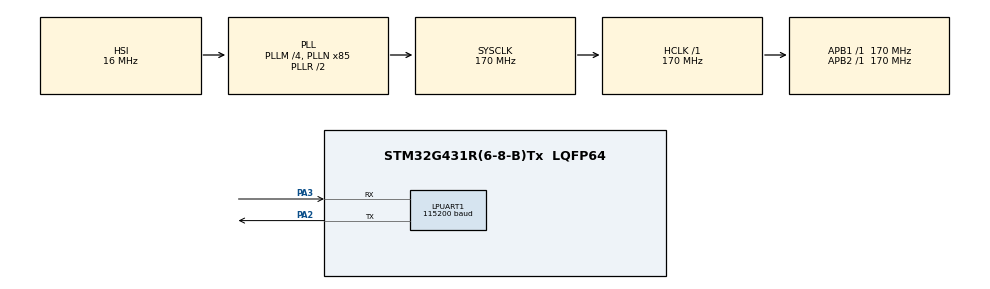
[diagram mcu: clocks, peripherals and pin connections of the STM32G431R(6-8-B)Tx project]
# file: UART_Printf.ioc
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FREERTOS.BinarySemaphores01=myBinarySem01,Dynamic,NULL
FREERTOS.Tasks01=defaultTask,0,128,StartDefaultTask,Default,NULL,Dynamic,NULL,NULL;printfTask,-3,128,StartPrintfTask,Default,NULL,Dynamic,NULL,NULL
FREERTOS.configUSE_NEWLIB_REENTRANT=1
LPUART1.BaudRate=115200
LPUART1.DMADisableonRxErrorParam-Asynchronous=UART_ADVFEATURE_DMA_ENABLEONRXERROR
LPUART1.DataInvertParam-Asynchronous=UART_ADVFEATURE_DATAINV_DISABLE
LPUART1.MSBFirstParam-Asynchronous=UART_ADVFEATURE_MSBFIRST_DISABLE
LPUART1.Mode-Asynchronous=UART_MODE_TX_RX
LPUART1.OneBitSampling=UART_ONE_BIT_SAMPLE_DISABLE
LPUART1.OverrunDisableParam-Asynchronous=UART_ADVFEATURE_OVERRUN_ENABLE
LPUART1.Parity-Asynchronous=UART_PARITY_ODD
LPUART1.RxPinLevelInvertParam-Asynchronous=UART_ADVFEATURE_RXINV_DISABLE
LPUART1.StopBits-Asynchronous=UART_STOPBITS_1
LPUART1.SwapParam-Asynchronous=UART_ADVFEATURE_SWAP_DISABLE
LPUART1.TxPinLevelInvertParam-Asynchronous=UART_ADVFEATURE_TXINV_DISABLE
LPUART1.WordLength=UART_WORDLENGTH_8B
Mcu.Family=STM32G4
Mcu.Name=STM32G431R(6-8-B)Tx
Mcu.Package=LQFP64
NVIC.PriorityGroup=NVIC_PRIORITYGROUP_4
NVIC.TIM6_DAC_IRQn=true\:15\:0\:false\:false\:true\:false\:false\:true\:true
NVIC.TimeBase=TIM6_DAC_IRQn
NVIC.TimeBaseIP=TIM6
PA2.GPIO_PuPd=GPIO_PULLUP
PA2.Mode=Asynchronous
PA2.Signal=LPUART1_TX
PA3.GPIO_PuPd=GPIO_PULLUP
PA3.Mode=Asynchronous
PA3.Signal=LPUART1_RX
ProjectManager.HeapSize=0x200
ProjectManager.StackSize=0x400
ProjectManager.TargetToolchain=STM32CubeIDE
RCC.ADC12Freq_Value=170000000
RCC.AHBFreq_Value=170000000
RCC.APB1Freq_Value=170000000
RCC.APB1TimFreq_Value=170000000
RCC.APB2Freq_Value=170000000
RCC.APB2TimFreq_Value=170000000
RCC.CortexFreq_Value=170000000
RCC.EXTERNAL_CLOCK_VALUE=12288000
RCC.HCLKFreq_Value=170000000
RCC.HSE_VALUE=24000000
RCC.HSI48_VALUE=48000000
RCC.HSI_VALUE=16000000
RCC.LSE_VALUE=32768
RCC.PLLM=RCC_PLLM_DIV4
RCC.PLLN=85
RCC.SYSCLKFreq_VALUE=170000000
RCC.SYSCLKSource=RCC_SYSCLKSOURCE_PLLCLK
RCC.USBFreq_Value=170000000
RCC.VCOOutputFreq_Value=340000000
VP_FREERTOS_VS_CMSIS_V1.Mode=CMSIS_V1
VP_SYS_VS_DBSignals.Mode=DisableDeadBatterySignals
VP_SYS_VS_tim6.Mode=TIM6
board=custom

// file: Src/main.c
/* USER CODE BEGIN Header */
/**
  ******************************************************************************
  * @file    UART/UART_Printf/Src/main.c
  * @author  MCD Application Team
  * @brief   This example shows how to retarget the C library printf function
  *          to the UART.
  ******************************************************************************
  * @attention
  *
  * Copyright (c) 2019 STMicroelectronics.
  * All rights reserved.
  *
  * This software is licensed under terms that can be found in the LICENSE file
  * in the root directory of this software component.
  * If no LICENSE file comes with this software, it is provided AS-IS.
  *
  ******************************************************************************
  */
/* USER CODE END Header */
#include "main.h"
#include "cmsis_os.h"
#include <stdarg.h>

UART_HandleTypeDef hlpuart1;

osThreadId defaultTaskHandle;
osThreadId printfTaskHandle;
osSemaphoreId myBinarySem01Handle;

void SystemClock_Config(void);
static void MX_GPIO_Init(void);
static void MX_LPUART1_UART_Init(void);
void StartDefaultTask(void const * argument);
void StartPrintfTask(void const * argument);

/* USER CODE BEGIN PFP */
#ifdef __GNUC__
/* With GCC, small printf (option LD Linker->Libraries->Small printf
   set to 'Yes') calls __io_putchar() */
#define PUTCHAR_PROTOTYPE int __io_putchar(int ch)
#else
#define PUTCHAR_PROTOTYPE int fputc(int ch, FILE *f)
#endif /* __GNUC__ */
/* USER CODE END PFP */

int main(void)
{
  /* USER CODE BEGIN 1 */

  /* STM32G4xx HAL library initialization:
       - Configure the Flash prefetch
       - Systick timer is configured by default as source of time base, but user
         can eventually implement his proper time base source (a general purpose
         timer for example or other time source), keeping in mind that Time base
         duration should be kept 1ms since PPP_TIMEOUT_VALUEs are defined and
         handled in milliseconds basis.
       - Set NVIC Group Priority to 4
       - Low Level Initialization
     */
  /* USER CODE END 1 */

  /* MCU Configuration--------------------------------------------------------*/

  /* Reset of all peripherals, Initializes the Flash interface and the Systick. */
  HAL_Init();

  /* Configure the system clock */
  SystemClock_Config();

  /* USER CODE BEGIN SysInit */
  /* Initialize BSP Led for LED2 */
  BSP_LED_Init(LED2);
  /* USER CODE END SysInit */

  /* Initialize all configured peripherals */
  MX_GPIO_Init();
  MX_LPUART1_UART_Init();
  /* USER CODE BEGIN 2 */

  /* Output a message on Hyperterminal using printf function */
  printf("\n\r UART Printf Example: retarget the C library printf function to the UART\n\r");

  /* USER CODE END 2 */

  /* Create the semaphores(s) */
  /* definition and creation of myBinarySem01 */
  osSemaphoreDef(myBinarySem01);
  myBinarySem01Handle = osSemaphoreCreate(osSemaphore(myBinarySem01), 1);

  /* Create the thread(s) */
  /* definition and creation of defaultTask */
  osThreadDef(defaultTask, StartDefaultTask, osPriorityNormal, 0, 128);
  defaultTaskHandle = osThreadCreate(osThread(defaultTask), NULL);

  /* definition and creation of printfTask */
  osThreadDef(printfTask, StartPrintfTask, osPriorityIdle, 0, 128);
  printfTaskHandle = osThreadCreate(osThread(printfTask), NULL);

  /* Start scheduler */
  osKernelStart();

  /* We should never get here as control is now taken by the scheduler */
  /* Infinite loop */
  while (1)
  {

  }
}

void SystemClock_Config(void)
{
  RCC_OscInitTypeDef RCC_OscInitStruct = {0};
  RCC_ClkInitTypeDef RCC_ClkInitStruct = {0};

  /** Configure the main internal regulator output voltage
  */
  HAL_PWREx_ControlVoltageScaling(PWR_REGULATOR_VOLTAGE_SCALE1_BOOST);

  /** Initializes the RCC Oscillators according to the specified parameters
  * in the RCC_OscInitTypeDef structure.
  */
  RCC_OscInitStruct.OscillatorType = RCC_OSCILLATORTYPE_HSI;
  RCC_OscInitStruct.HSIState = RCC_HSI_ON;
  RCC_OscInitStruct.HSICalibrationValue = RCC_HSICALIBRATION_DEFAULT;
  RCC_OscInitStruct.PLL.PLLState = RCC_PLL_ON;
  RCC_OscInitStruct.PLL.PLLSource = RCC_PLLSOURCE_HSI;
  RCC_OscInitStruct.PLL.PLLM = RCC_PLLM_DIV4;
  RCC_OscInitStruct.PLL.PLLN = 85;
  RCC_OscInitStruct.PLL.PLLP = RCC_PLLP_DIV2;
  RCC_OscInitStruct.PLL.PLLQ = RCC_PLLQ_DIV2;
  RCC_OscInitStruct.PLL.PLLR = RCC_PLLR_DIV2;
  if (HAL_RCC_OscConfig(&RCC_OscInitStruct) != HAL_OK)
  {
    Error_Handler();
  }

  /** Initializes the CPU, AHB and APB buses clocks
  */
  RCC_ClkInitStruct.ClockType = RCC_CLOCKTYPE_HCLK|RCC_CLOCKTYPE_SYSCLK
                              |RCC_CLOCKTYPE_PCLK1|RCC_CLOCKTYPE_PCLK2;
  RCC_ClkInitStruct.SYSCLKSource = RCC_SYSCLKSOURCE_PLLCLK;
  RCC_ClkInitStruct.AHBCLKDivider = RCC_SYSCLK_DIV1;
  RCC_ClkInitStruct.APB1CLKDivider = RCC_HCLK_DIV1;
  RCC_ClkInitStruct.APB2CLKDivider = RCC_HCLK_DIV1;

  if (HAL_RCC_ClockConfig(&RCC_ClkInitStruct, FLASH_LATENCY_4) != HAL_OK)
  {
    Error_Handler();
  }
}

static void MX_LPUART1_UART_Init(void)
{

  hlpuart1.Instance = LPUART1;
  hlpuart1.Init.BaudRate = 115200;
  hlpuart1.Init.WordLength = UART_WORDLENGTH_8B;
  hlpuart1.Init.StopBits = UART_STOPBITS_1;
  hlpuart1.Init.Parity = UART_PARITY_NONE;
  hlpuart1.Init.Mode = UART_MODE_TX_RX;
  hlpuart1.Init.HwFlowCtl = UART_HWCONTROL_NONE;
  hlpuart1.Init.OneBitSampling = UART_ONE_BIT_SAMPLE_DISABLE;
  hlpuart1.Init.ClockPrescaler = UART_PRESCALER_DIV1;
  hlpuart1.AdvancedInit.AdvFeatureInit = UART_ADVFEATURE_NO_INIT;
  if (HAL_UART_Init(&hlpuart1) != HAL_OK)
  {
    Error_Handler();
  }
  if (HAL_UARTEx_SetTxFifoThreshold(&hlpuart1, UART_TXFIFO_THRESHOLD_1_8) != HAL_OK)
  {
    Error_Handler();
  }
  if (HAL_UARTEx_SetRxFifoThreshold(&hlpuart1, UART_RXFIFO_THRESHOLD_1_8) != HAL_OK)
  {
    Error_Handler();
  }
  if (HAL_UARTEx_DisableFifoMode(&hlpuart1) != HAL_OK)
  {
    Error_Handler();
  }

}

static void MX_GPIO_Init(void)
{

  /* GPIO Ports Clock Enable */
  __HAL_RCC_GPIOA_CLK_ENABLE();

}

/* USER CODE BEGIN 4 */
static void UARTPrintf(const char *pFormat,...)
{
	char buffer[64];
	va_list args;
	va_start(args, pFormat);
	__disable_irq();
	int len = vsprintf(buffer, pFormat, args);
	__enable_irq();

	for (int i = 0; i < len; i++)
	{
		__disable_irq();
		HAL_UART_Transmit(&hlpuart1, (uint8_t*) &buffer[i], 1, HAL_MAX_DELAY);
		__enable_irq();
	}
	va_end(args);
}

/**
  * @brief  Retargets the C library printf function to the USART.
  * @param  None
  * @retval None
  */
PUTCHAR_PROTOTYPE
{
  /* Place your implementation of fputc here */
  /* e.g. write a character to the LPUART1 and Loop until the end of transmission */
  HAL_UART_Transmit(&hlpuart1, (uint8_t *)&ch, 1, HAL_MAX_DELAY);
  return ch;
}

/* USER CODE END 4 */

void StartDefaultTask(void const * argument)
{
  /* USER CODE BEGIN 5 */
  /* Infinite loop */
  for(;;)
  {
	  UARTPrintf("\n\r Start Default Task\n\r");
	  osDelay(1000);
  }
  /* USER CODE END 5 */
}

void StartPrintfTask(void const * argument)
{
  /* USER CODE BEGIN StartPrintfTask */
  /* Infinite loop */
  for(;;)
  {
	UARTPrintf("** Start Printf Task. ** \n\r");
	osDelay(1000);
  }
  /* USER CODE END StartPrintfTask */
}

void HAL_TIM_PeriodElapsedCallback(TIM_HandleTypeDef *htim)
{
  if (htim->Instance == TIM6) {
    HAL_IncTick();
  }
}

void Error_Handler(void)
{
  /* USER CODE BEGIN Error_Handler_Debug */
  /* User can add his own implementation to report the HAL error return state */
  while (1)
  {
    /* Toggle LED2 for error */
    BSP_LED_Toggle(LED2);
    HAL_Delay(500);
  }
  /* USER CODE END Error_Handler_Debug */
}
